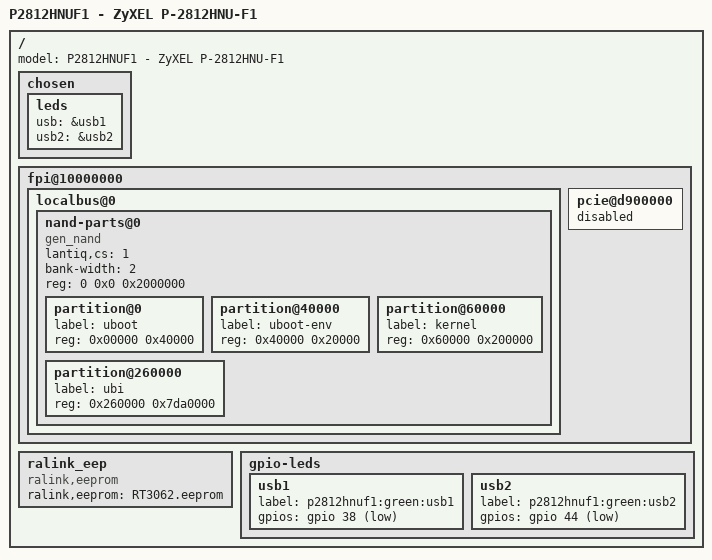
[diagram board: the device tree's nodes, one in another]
/dts-v1/;

/include/ "P2812HNUFX.dtsi"

/ {
	model = "P2812HNUF1 - ZyXEL P-2812HNU-F1";

	chosen {
		leds {
			usb = &usb1;
			usb2 = &usb2;
		};
	};

	fpi@10000000 {
		localbus@0 {
			nand-parts@0 {
				compatible = "gen_nand", "lantiq,nand-xway";
				lantiq,cs = <1>;
				bank-width = <2>;
				reg = <0 0x0 0x2000000>;
				#address-cells = <1>;
				#size-cells = <1>;

				partition@0 {
					label = "uboot";
					reg = <0x00000 0x40000>;
				};
				partition@40000 {
					label = "uboot-env";
					reg = <0x40000 0x20000>;
				};
				partition@60000 {
					label = "kernel";
					reg = <0x60000 0x200000>;
				};
				partition@260000 {
					label = "ubi";
					reg = <0x260000 0x7da0000>;
				};
			};
		};
		pcie@d900000 {
			status = "disabled";
		};
	};

	ralink_eep {
		compatible = "ralink,eeprom";
		ralink,eeprom = "RT3062.eeprom";
	};

	gpio-leds {
		usb1: usb1 {
			label = "p2812hnuf1:green:usb1";
			gpios = <&gpio 38 1>;
		};
		usb2: usb2 {
			label = "p2812hnuf1:green:usb2";
			gpios = <&gpio 44 1>;
		};
	};
};
